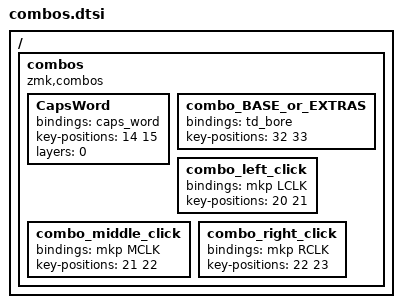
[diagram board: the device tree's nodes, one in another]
/ {
    combos {
        compatible = "zmk,combos";

        /* Positions for 3x5 layout:
         * ╭──────┬──────┬──────┬──────┬──────╮  ╭──────┬──────┬──────┬──────┬──────╮
         *    00     01     02     03    04         05     06     07     08     09
         * ├──────┼──────┼──────┼──────┼──────┤  ├──────┼──────┼──────┼──────┼──────┤
         *    10     11     12     13    14         15     16     17     18     19
         * ├──────┼──────┼──────┼──────┼──────┤  ├──────┼──────┼──────┼──────┼──────┤
         *    20     21     22     23    24         25     26     27     28     29
         * ╰──────┴──────┼──────┼──────┼──────┤  ├──────┼──────┼──────┴──────┴──────╯
         *                  30     31     32        33     34
         *               ╰──────┴──────┴──────╯  ╰──────┴──────╯
         */

        CapsWord {
            bindings = <&caps_word>;
            key-positions = <14 15>;  /* G + H */
            layers = <0>;
        };

        combo_BASE_or_EXTRAS {
            bindings = <&td_bore>;
            key-positions = <32 33>;  /* inner thumbs */
        };

        combo_left_click {
            bindings = <&mkp LCLK>;
            key-positions = <20 21>;  /* Z + X */
        };

        combo_middle_click {
            bindings = <&mkp MCLK>;
            key-positions = <21 22>;  /* X + C */
        };

        combo_right_click {
            bindings = <&mkp RCLK>;
            key-positions = <22 23>;  /* C + V */
        };
    };
};
